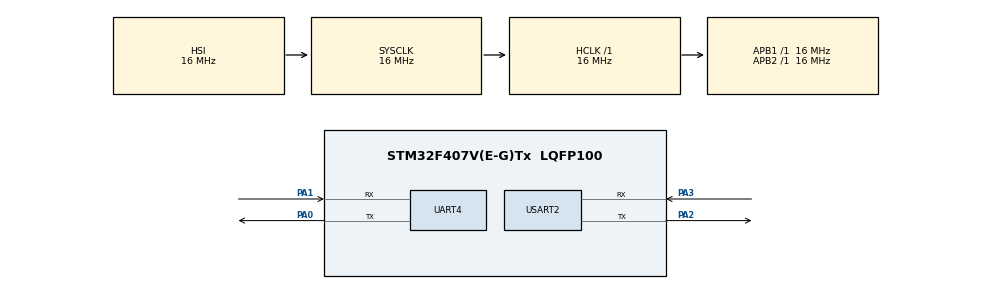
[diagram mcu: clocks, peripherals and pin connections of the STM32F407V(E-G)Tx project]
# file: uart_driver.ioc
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FREERTOS.Queues01=uart2_BytesReceived,8,uint16_t,0,Static,uart2_BytesReceivedBuffer,uart2_BytesReceivedControlBlock
FREERTOS.Tasks01=defaultTask,24,128,StartDefaultTask,Default,NULL,Dynamic,NULL,NULL;mypolledUartRec,8,128,polledUartReceive,Default,NULL,Static,polledUartReceiBuffer,polledUartReceiControlBlock;myTask03,8,128,uartPrintOutTask,Default,NULL,Static,myTask03Buffer,myTask03ControlBlock
Mcu.Family=STM32F4
Mcu.Name=STM32F407V(E-G)Tx
Mcu.Package=LQFP100
NVIC.PriorityGroup=NVIC_PRIORITYGROUP_4
NVIC.TIM7_IRQn=true\:0\:0\:false\:false\:true\:false\:false\:true
NVIC.TimeBase=TIM7_IRQn
NVIC.TimeBaseIP=TIM7
PA0-WKUP.Mode=Asynchronous
PA0-WKUP.Signal=UART4_TX
PA1.Mode=Asynchronous
PA1.Signal=UART4_RX
PA2.Mode=Asynchronous
PA2.Signal=USART2_TX
PA3.Mode=Asynchronous
PA3.Signal=USART2_RX
ProjectManager.HeapSize=0x200
ProjectManager.StackSize=0x400
ProjectManager.TargetToolchain=STM32CubeIDE
RCC.AHBFreq_Value=16000000
RCC.APB1Freq_Value=16000000
RCC.APB2Freq_Value=16000000
RCC.CortexFreq_Value=16000000
RCC.HSE_VALUE=25000000
RCC.HSI_VALUE=16000000
RCC.LSE_VALUE=32768
RCC.SYSCLKFreq_VALUE=16000000
RCC.VCOOutputFreq_Value=192000000
UART4.VirtualMode=Asynchronous
USART2.VirtualMode=VM_ASYNC
VP_FREERTOS_VS_CMSIS_V2.Mode=CMSIS_V2
VP_SYS_VS_tim7.Mode=TIM7
board=custom

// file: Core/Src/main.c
/* USER CODE BEGIN Header */
/**
  ******************************************************************************
  * @file           : main.c
  * @brief          : Main program body
  ******************************************************************************
  * @attention
  *
  * <h2><center>&copy; Copyright (c) 2020 STMicroelectronics.
  * All rights reserved.</center></h2>
  *
  * This software component is licensed by ST under BSD 3-Clause license,
  * the "License"; You may not use this file except in compliance with the
  * License. You may obtain a copy of the License at:
  *                        opensource.org/licenses/BSD-3-Clause
  *
  ******************************************************************************
  */
/* USER CODE END Header */
#include "main.h"
#include "cmsis_os.h"
#include "usart.h"
#include "gpio.h"

/* USER CODE BEGIN PTD */
#include "SEGGER_SYSVIEW.h"
#include "SEGGER_RTT.h"
/* USER CODE END PTD */

void SystemClock_Config(void);
void MX_FREERTOS_Init(void);

int main(void)
{

  /* MCU Configuration--------------------------------------------------------*/

  /* Reset of all peripherals, Initializes the Flash interface and the Systick. */
  HAL_Init();

  /* USER CODE BEGIN Init */
  SEGGER_SYSVIEW_Conf();
  SEGGER_SYSVIEW_Start();
  /* USER CODE END Init */

  /* Configure the system clock */
  SystemClock_Config();

  /* Initialize all configured peripherals */
  MX_GPIO_Init();
  MX_UART4_Init();
  MX_USART2_UART_Init();

  /* Init scheduler */
  osKernelInitialize();  /* Call init function for freertos objects (in freertos.c) */
  MX_FREERTOS_Init();
  /* Start scheduler */
  osKernelStart();

  /* We should never get here as control is now taken by the scheduler */
  /* Infinite loop */
  while (1)
  {

  }
}

void SystemClock_Config(void)
{
  RCC_OscInitTypeDef RCC_OscInitStruct = {0};
  RCC_ClkInitTypeDef RCC_ClkInitStruct = {0};

  /** Configure the main internal regulator output voltage
  */
  __HAL_RCC_PWR_CLK_ENABLE();
  __HAL_PWR_VOLTAGESCALING_CONFIG(PWR_REGULATOR_VOLTAGE_SCALE1);
  /** Initializes the RCC Oscillators according to the specified parameters
  * in the RCC_OscInitTypeDef structure.
  */
  RCC_OscInitStruct.OscillatorType = RCC_OSCILLATORTYPE_HSI;
  RCC_OscInitStruct.HSIState = RCC_HSI_ON;
  RCC_OscInitStruct.HSICalibrationValue = RCC_HSICALIBRATION_DEFAULT;
  RCC_OscInitStruct.PLL.PLLState = RCC_PLL_NONE;
  if (HAL_RCC_OscConfig(&RCC_OscInitStruct) != HAL_OK)
  {
    Error_Handler();
  }
  /** Initializes the CPU, AHB and APB buses clocks
  */
  RCC_ClkInitStruct.ClockType = RCC_CLOCKTYPE_HCLK|RCC_CLOCKTYPE_SYSCLK
                              |RCC_CLOCKTYPE_PCLK1|RCC_CLOCKTYPE_PCLK2;
  RCC_ClkInitStruct.SYSCLKSource = RCC_SYSCLKSOURCE_HSI;
  RCC_ClkInitStruct.AHBCLKDivider = RCC_SYSCLK_DIV1;
  RCC_ClkInitStruct.APB1CLKDivider = RCC_HCLK_DIV1;
  RCC_ClkInitStruct.APB2CLKDivider = RCC_HCLK_DIV1;

  if (HAL_RCC_ClockConfig(&RCC_ClkInitStruct, FLASH_LATENCY_0) != HAL_OK)
  {
    Error_Handler();
  }
}

void HAL_TIM_PeriodElapsedCallback(TIM_HandleTypeDef *htim)
{
  if (htim->Instance == TIM7) {
    HAL_IncTick();
  }
}

void Error_Handler(void)
{
}

/************************ (C) COPYRIGHT STMicroelectronics *****END OF FILE****/

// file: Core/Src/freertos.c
/* USER CODE BEGIN Header */
/**
  ******************************************************************************
  * File Name          : freertos.c
  * Description        : Code for freertos applications
  ******************************************************************************
  * @attention
  *
  * <h2><center>&copy; Copyright (c) 2020 STMicroelectronics.
  * All rights reserved.</center></h2>
  *
  * This software component is licensed by ST under Ultimate Liberty license
  * SLA0044, the "License"; You may not use this file except in compliance with
  * the License. You may obtain a copy of the License at:
  *                             www.st.com/SLA0044
  *
  ******************************************************************************
  */
/* USER CODE END Header */

#include "FreeRTOS.h"
#include "task.h"
#include "main.h"
#include "cmsis_os.h"

/* USER CODE BEGIN Includes */
#include "queue.h"
/* USER CODE END Includes */

typedef StaticTask_t osStaticThreadDef_t;
typedef StaticQueue_t osStaticMessageQDef_t;

/* Definitions for defaultTask */
osThreadId_t defaultTaskHandle;
const osThreadAttr_t defaultTask_attributes = {
  .name = "defaultTask",
  .priority = (osPriority_t) osPriorityNormal,
  .stack_size = 128 * 4
};
/* Definitions for mypolledUartRec */
osThreadId_t mypolledUartRecHandle;
uint32_t polledUartReceiBuffer[ 128 ];
osStaticThreadDef_t polledUartReceiControlBlock;
const osThreadAttr_t mypolledUartRec_attributes = {
  .name = "mypolledUartRec",
  .stack_mem = &polledUartReceiBuffer[0],
  .stack_size = sizeof(polledUartReceiBuffer),
  .cb_mem = &polledUartReceiControlBlock,
  .cb_size = sizeof(polledUartReceiControlBlock),
  .priority = (osPriority_t) osPriorityLow,
};
/* Definitions for myTask03 */
osThreadId_t myTask03Handle;
uint32_t myTask03Buffer[ 128 ];
osStaticThreadDef_t myTask03ControlBlock;
const osThreadAttr_t myTask03_attributes = {
  .name = "myTask03",
  .stack_mem = &myTask03Buffer[0],
  .stack_size = sizeof(myTask03Buffer),
  .cb_mem = &myTask03ControlBlock,
  .cb_size = sizeof(myTask03ControlBlock),
  .priority = (osPriority_t) osPriorityLow,
};
/* Definitions for uart2_BytesReceived */
osMessageQueueId_t uart2_BytesReceivedHandle;
uint8_t uart2_BytesReceivedBuffer[ 8 * sizeof( uint16_t ) ];
osStaticMessageQDef_t uart2_BytesReceivedControlBlock;
const osMessageQueueAttr_t uart2_BytesReceived_attributes = {
  .name = "uart2_BytesReceived",
  .cb_mem = &uart2_BytesReceivedControlBlock,
  .cb_size = sizeof(uart2_BytesReceivedControlBlock),
  .mq_mem = &uart2_BytesReceivedBuffer,
  .mq_size = sizeof(uart2_BytesReceivedBuffer)
};

void StartDefaultTask(void *argument);
void polledUartReceive(void *argument);
void uartPrintOutTask(void *argument);

void MX_FREERTOS_Init(void); /* (MISRA C 2004 rule 8.1) */

void MX_FREERTOS_Init(void) {

  /* Create the queue(s) */
  /* creation of uart2_BytesReceived */
  uart2_BytesReceivedHandle = osMessageQueueNew (8, sizeof(uint16_t), &uart2_BytesReceived_attributes);

  /* Create the thread(s) */
  /* creation of defaultTask */
  defaultTaskHandle = osThreadNew(StartDefaultTask, NULL, &defaultTask_attributes);

  /* creation of mypolledUartRec */
  mypolledUartRecHandle = osThreadNew(polledUartReceive, NULL, &mypolledUartRec_attributes);

  /* creation of myTask03 */
  myTask03Handle = osThreadNew(uartPrintOutTask, NULL, &myTask03_attributes);

}

void StartDefaultTask(void *argument)
{
  for(;;)
  {
    osDelay(1);
  }
}

void polledUartReceive(void *argument)
{
  /* USER CODE BEGIN polledUartReceive */
	uint8_t nextByte;
  /* Infinite loop */
  for(;;)
  {
	  while(!(USART2->SR & USART_SR_RXNE_Msk));
	  nextByte = USART2->DR;
	  xQueueSend(uart2_BytesReceivedHandle, &nextByte, 0);
  }
  /* USER CODE END polledUartReceive */
}

void uartPrintOutTask(void *argument)
{
  /* USER CODE BEGIN uartPrintOutTask */
  char nextByte;
  /* Infinite loop */
  for(;;)
  {
	  xQueueReceive(uart2_BytesReceivedHandle, &nextByte, 5000);
	  SEGGER_SYSVIEW_PrintfHost("%c", nextByte);
  }
  /* USER CODE END uartPrintOutTask */
}

/************************ (C) COPYRIGHT STMicroelectronics *****END OF FILE****/
